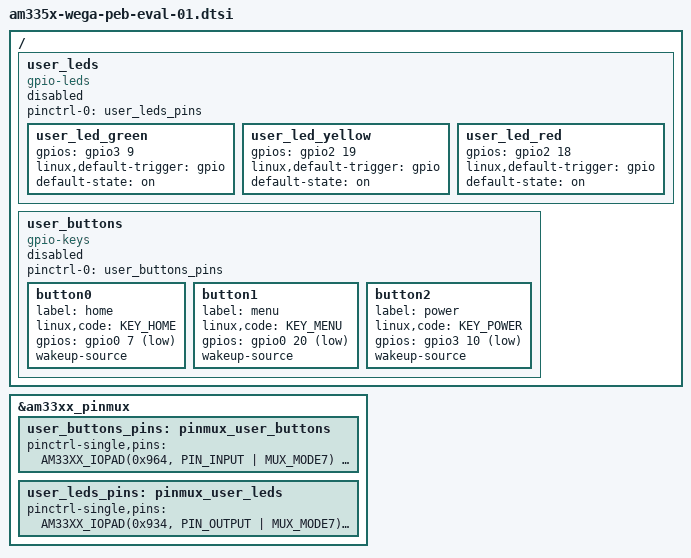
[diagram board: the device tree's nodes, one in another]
/* Copyright (C) 2016-2017 Phytec Messtechnik GmbH
 *
 * This program is free software; you can redistribute it and/or modify
 * it under the terms of the GNU General Public License version 2 as
 * published by the Free Software Foundation.
 */

#include <dt-bindings/input/input.h>

&am33xx_pinmux {
	user_buttons_pins: pinmux_user_buttons {
		pinctrl-single,pins = <
			AM33XX_IOPAD(0x964, PIN_INPUT | MUX_MODE7)	/* ecap0_in_pwm0_out.gpio0_7	*/
			AM33XX_IOPAD(0x9b4, PIN_INPUT | MUX_MODE7)	/* xdma_event_intr1.gpio0_20	*/
			AM33XX_IOPAD(0x930, PIN_INPUT | MUX_MODE7)	/* mii1_rx_clk.gpio3_10		*/
		>;
	};

	user_leds_pins: pinmux_user_leds {
		pinctrl-single,pins = <
			AM33XX_IOPAD(0x934, PIN_OUTPUT | MUX_MODE7)	/* mii1_rxd3.gpio2_18	*/
			AM33XX_IOPAD(0x938, PIN_OUTPUT | MUX_MODE7)	/* mii1_rxd2.gpio2_19	*/
			AM33XX_IOPAD(0x92c, PIN_OUTPUT | MUX_MODE7)	/* mii1_tx_clk.gpio3_9	*/
		>;
	};
};

/ {
	user_leds: user_leds {
		compatible = "gpio-leds";
		pinctrl-names = "default";
		pinctrl-0 = <&user_leds_pins>;
		status = "disabled";

		user_led_green {
			gpios = <&gpio3 9 GPIO_ACTIVE_HIGH>;
			linux,default-trigger = "gpio";
			default-state = "on";
		};

		user_led_yellow {
			gpios = <&gpio2 19 GPIO_ACTIVE_HIGH>;
			linux,default-trigger = "gpio";
			default-state = "on";
		};

		user_led_red {
			gpios = <&gpio2 18 GPIO_ACTIVE_HIGH>;
			linux,default-trigger = "gpio";
			default-state = "on";
		};
	};

	user_buttons: user_buttons {
		compatible = "gpio-keys";
		pinctrl-names = "default";
		pinctrl-0 = <&user_buttons_pins>;
		status = "disabled";

		button0 {
			label = "home";
			linux,code = <KEY_HOME>;
			gpios = <&gpio0 7 GPIO_ACTIVE_LOW>;
			wakeup-source;
		};

		button1 {
			label = "menu";
			linux,code = <KEY_MENU>;
			gpios = <&gpio0 20 GPIO_ACTIVE_LOW>;
			wakeup-source;
		};

		button2 {
			label = "power";
			linux,code = <KEY_POWER>;
			gpios = <&gpio3 10 GPIO_ACTIVE_LOW>;
			wakeup-source;
		};
	};
};
